AUTOSAR XML (schema 4-0-3)
package /WindowMgmt
  composition sw component type WindowComposition
    component winCtrl: type=/WindowMgmt/WindowControl
    component antiPinch: type=/WindowMgmt/AntiPinch
    assembly sw connector prototype conn_pinch_cmd: provider=WindowControl.pinchCommand, requester=AntiPinch.pinchCommand
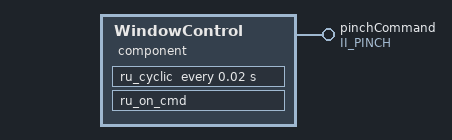
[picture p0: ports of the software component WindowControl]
  sw component type WindowControl
    provide port pinchCommand: provided-com-spec=server-com-spec=II_PINCH, provided-interface=II_PINCH
    internal behavior ib_win
      timing event ev_cyclic_20ms: start-on-event=ru_cyclic, period=0.02
      operation invoked event ev_pinch_cmd: start-on-event=ru_on_cmd, operation=pinchCommand
      runnable ru_cyclic: symbol=WindowControl_Cyclic20ms
      runnable ru_on_cmd: symbol=WindowControl_OnPinchCommand
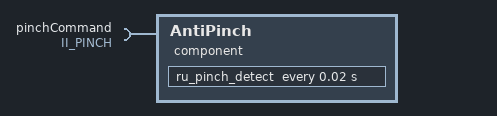
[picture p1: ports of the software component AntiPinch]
  sw component type AntiPinch
    require port pinchCommand: required-interface=II_PINCH
    internal behavior ib_pinch
      timing event ev_pinch_20ms: start-on-event=ru_pinch_detect, period=0.02
      runnable ru_pinch_detect: symbol=AntiPinch_Detect
  port interface II_PINCH
    operation SetPinchCommand
      arg cmd: type=/WindowMgmt/uint8, direction=IN
  data type mapping set uint8
